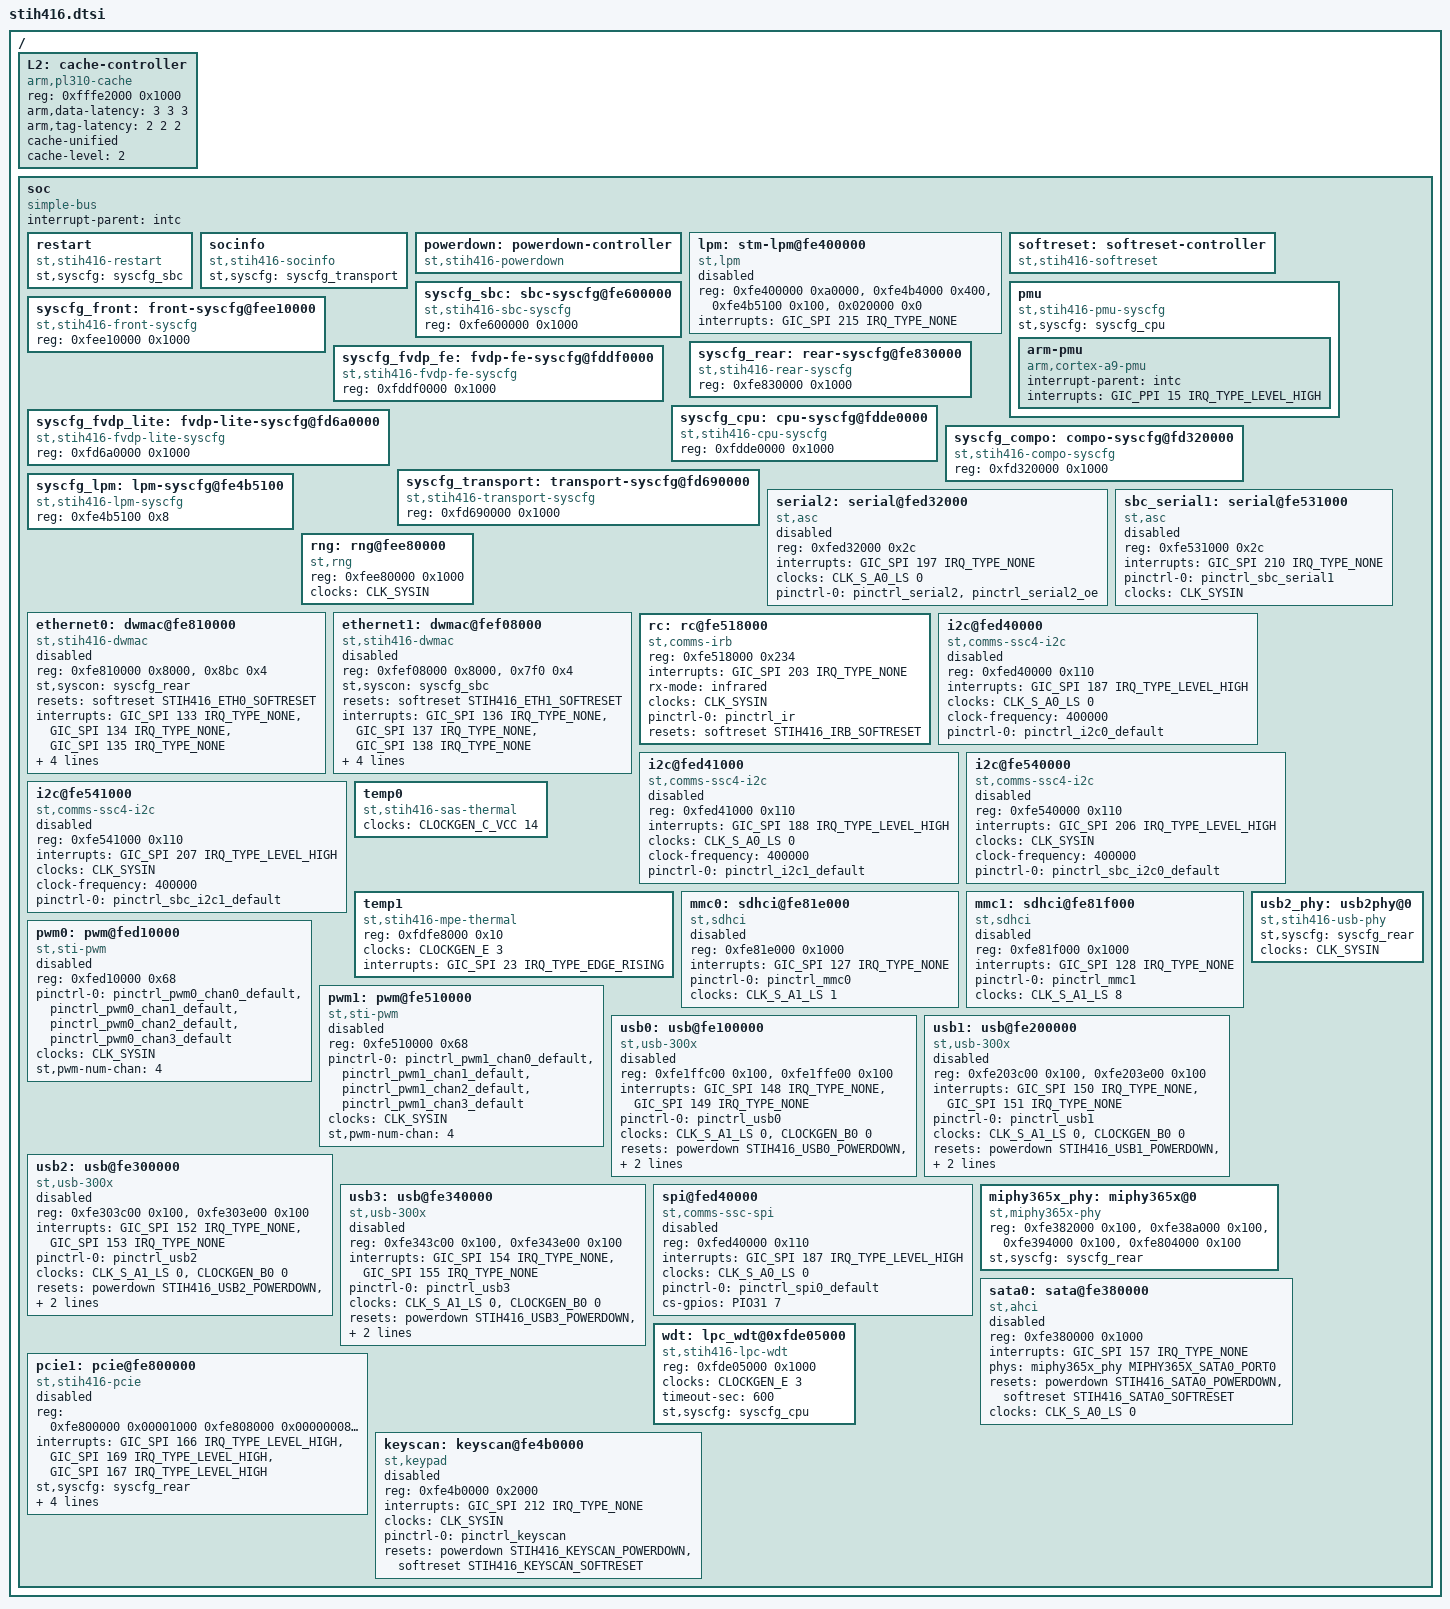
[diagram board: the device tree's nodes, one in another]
/*
 * Copyright (C) 2012 STMicroelectronics Limited.
 * Author: Srinivas Kandagatla <srinivas.kandagatla@st.com>
 *
 * This program is free software; you can redistribute it and/or modify
 * it under the terms of the GNU General Public License version 2 as
 * publishhed by the Free Software Foundation.
 */
#include <dt-bindings/interrupt-controller/arm-gic.h>
#include <dt-bindings/reset-controller/stih416-resets.h>
#include <dt-bindings/phy/phy-miphy365x.h>
#include "stih41x.dtsi"
#include "stih416-clock.dtsi"
#include "stih416-pinctrl.dtsi"
/ {
	L2: cache-controller {
		compatible = "arm,pl310-cache";
		reg = <0xfffe2000 0x1000>;
		arm,data-latency = <3 3 3>;
		arm,tag-latency = <2 2 2>;
		cache-unified;
		cache-level = <2>;
	};

	soc {
		#address-cells = <1>;
		#size-cells = <1>;
		interrupt-parent = <&intc>;
		ranges;
		compatible = "simple-bus";

		restart {
			compatible = "st,stih416-restart";
			st,syscfg = <&syscfg_sbc>;
		};

		socinfo {
			compatible = "st,stih416-socinfo";
			st,syscfg = <&syscfg_transport>;
		};

		powerdown: powerdown-controller {
			#reset-cells = <1>;
			compatible = "st,stih416-powerdown";
		};

		lpm:stm-lpm@fe400000 {
			compatible = "st,lpm";
			reg = <0xfe400000 0xa0000>,
			      <0xfe4b4000 0x400>,
			      <0xfe4b5100 0x100>,
			      <0x020000 0x0>;
			reg-names = "base", "mailbox", "confreg", "pmem";
			interrupts = <GIC_SPI 215 IRQ_TYPE_NONE>;
			status = "disabled";
		};

		softreset: softreset-controller {
			#reset-cells = <1>;
			compatible = "st,stih416-softreset";
		};

		pmu {
			compatible = "st,stih416-pmu-syscfg";
			st,syscfg = <&syscfg_cpu>;

			arm-pmu {
				interrupt-parent = <&intc>;
				compatible = "arm,cortex-a9-pmu";
				interrupts = <GIC_PPI 15 IRQ_TYPE_LEVEL_HIGH>;
			};
		};

		syscfg_sbc:sbc-syscfg@fe600000{
			compatible = "st,stih416-sbc-syscfg", "syscon";
			reg = <0xfe600000 0x1000>;
		};

		syscfg_front:front-syscfg@fee10000{
			compatible = "st,stih416-front-syscfg", "syscon";
			reg = <0xfee10000 0x1000>;
		};

		syscfg_rear:rear-syscfg@fe830000{
			compatible = "st,stih416-rear-syscfg", "syscon";
			reg = <0xfe830000 0x1000>;
		};

		/* MPE */
		syscfg_fvdp_fe:fvdp-fe-syscfg@fddf0000{
			compatible = "st,stih416-fvdp-fe-syscfg", "syscon";
			reg = <0xfddf0000 0x1000>;
		};

		syscfg_fvdp_lite:fvdp-lite-syscfg@fd6a0000{
			compatible = "st,stih416-fvdp-lite-syscfg", "syscon";
			reg = <0xfd6a0000 0x1000>;
		};

		syscfg_cpu:cpu-syscfg@fdde0000{
			compatible = "st,stih416-cpu-syscfg", "syscon";
			reg = <0xfdde0000 0x1000>;
		};

		syscfg_compo:compo-syscfg@fd320000{
			compatible = "st,stih416-compo-syscfg", "syscon";
			reg = <0xfd320000 0x1000>;
		};

		syscfg_transport:transport-syscfg@fd690000{
			compatible = "st,stih416-transport-syscfg", "syscon";
			reg = <0xfd690000 0x1000>;
		};

		syscfg_lpm:lpm-syscfg@fe4b5100{
			compatible = "st,stih416-lpm-syscfg", "syscon";
			reg = <0xfe4b5100 0x8>;
		};

		serial2: serial@fed32000{
			compatible = "st,asc";
			status = "disabled";
			reg = <0xfed32000 0x2c>;
			interrupts = <GIC_SPI 197 IRQ_TYPE_NONE>;
			clocks = <&CLK_S_A0_LS 0>;
			pinctrl-names = "default";
			pinctrl-0 = <&pinctrl_serial2 &pinctrl_serial2_oe>;
		};

		/* SBC_UART1 */
		sbc_serial1: serial@fe531000 {
			compatible = "st,asc";
			status = "disabled";
			reg = <0xfe531000 0x2c>;
			interrupts = <GIC_SPI 210 IRQ_TYPE_NONE>;
			pinctrl-names = "default";
			pinctrl-0 = <&pinctrl_sbc_serial1>;
			clocks = <&CLK_SYSIN>;
		};

		/* RNG */
		rng: rng@fee80000 {
			compatible = "st,rng";
			reg = <0xfee80000 0x1000>;
			clocks = <&CLK_SYSIN>;
		};

		ethernet0: dwmac@fe810000 {
			device_type = "network";
			status = "disabled";
			compatible = "st,stih416-dwmac", "snps,dwmac", "snps,dwmac-3.710";
			reg = <0xfe810000 0x8000>, <0x8bc 0x4>;
			reg-names = "stmmaceth", "sti-ethconf";
			st,syscon = <&syscfg_rear>;
			resets = <&softreset STIH416_ETH0_SOFTRESET>;
			reset-names = "stmmaceth";
			interrupts = <GIC_SPI 133 IRQ_TYPE_NONE>,
				     <GIC_SPI 134 IRQ_TYPE_NONE>,
				     <GIC_SPI 135 IRQ_TYPE_NONE>;

			interrupt-names = "macirq", "eth_wake_irq", "eth_lpi";

			snps,pbl = <32>;
			snps,mixed-burst;

			pinctrl-names = "default";
			pinctrl-0 = <&pinctrl_mii0>;
			clock-names = "stmmaceth", "sti-ethclk";
			clocks = <&CLK_S_A1_LS 0>, <&CLK_S_A1_LS 3>;
		};

		ethernet1: dwmac@fef08000 {
			device_type = "network";
			status = "disabled";
			compatible = "st,stih416-dwmac", "snps,dwmac", "snps,dwmac-3.710";
			reg = <0xfef08000 0x8000>, <0x7f0 0x4>;
			reg-names = "stmmaceth", "sti-ethconf";
			st,syscon = <&syscfg_sbc>;
			resets = <&softreset STIH416_ETH1_SOFTRESET>;
			reset-names = "stmmaceth";

			interrupts = <GIC_SPI 136 IRQ_TYPE_NONE>,
					     <GIC_SPI 137 IRQ_TYPE_NONE>,
					     <GIC_SPI 138 IRQ_TYPE_NONE>;

			interrupt-names = "macirq", "eth_wake_irq", "eth_lpi";

			snps,pbl = <32>;
			snps,mixed-burst;

			pinctrl-names = "default";
			pinctrl-0 = <&pinctrl_mii1>;
			clock-names = "stmmaceth", "sti-ethclk";
			clocks = <&CLK_S_A0_LS 0>, <&CLK_S_A0_LS 4>;
		};

		rc: rc@fe518000 {
			compatible = "st,comms-irb";
			reg = <0xfe518000 0x234>;
			interrupts = <GIC_SPI 203 IRQ_TYPE_NONE>;
			rx-mode = "infrared";
			clocks = <&CLK_SYSIN>;
			pinctrl-names = "default";
			pinctrl-0 = <&pinctrl_ir>;
			resets = <&softreset STIH416_IRB_SOFTRESET>;
		};

		i2c@fed40000 {
			compatible = "st,comms-ssc4-i2c";
			reg	= <0xfed40000 0x110>;
			interrupts = <GIC_SPI 187 IRQ_TYPE_LEVEL_HIGH>;
			#address-cells = <1>;
			#size-cells = <0>;
			clocks = <&CLK_S_A0_LS 0>;
			clock-names	= "ssc";
			clock-frequency = <400000>;
			pinctrl-names = "default";
			pinctrl-0 = <&pinctrl_i2c0_default>;

			status = "disabled";
		};

		i2c@fed41000 {
			compatible = "st,comms-ssc4-i2c";
			reg = <0xfed41000 0x110>;
			interrupts = <GIC_SPI 188 IRQ_TYPE_LEVEL_HIGH>;
			#address-cells = <1>;
			#size-cells = <0>;
			clocks = <&CLK_S_A0_LS 0>;
			clock-names	= "ssc";
			clock-frequency = <400000>;
			pinctrl-names = "default";
			pinctrl-0 = <&pinctrl_i2c1_default>;

			status = "disabled";
		};

		i2c@fe540000 {
			compatible = "st,comms-ssc4-i2c";
			reg = <0xfe540000 0x110>;
			interrupts = <GIC_SPI 206 IRQ_TYPE_LEVEL_HIGH>;
			#address-cells = <1>;
			#size-cells = <0>;
			clocks = <&CLK_SYSIN>;
			clock-names = "ssc";
			clock-frequency = <400000>;
			pinctrl-names = "default";
			pinctrl-0 = <&pinctrl_sbc_i2c0_default>;

			status = "disabled";
		};

		i2c@fe541000 {
			compatible = "st,comms-ssc4-i2c";
			reg = <0xfe541000 0x110>;
			interrupts = <GIC_SPI 207 IRQ_TYPE_LEVEL_HIGH>;
			#address-cells = <1>;
			#size-cells = <0>;
			clocks = <&CLK_SYSIN>;
			clock-names = "ssc";
			clock-frequency = <400000>;
			pinctrl-names = "default";
			pinctrl-0 = <&pinctrl_sbc_i2c1_default>;

			status = "disabled";
		};

		temp0{
			compatible = "st,stih416-sas-thermal";
			clock-names = "thermal";
			clocks = <&CLOCKGEN_C_VCC 14>;
		};

		temp1{
			compatible = "st,stih416-mpe-thermal";
			reg = <0xfdfe8000 0x10>;
			clock-names = "thermal";
			clocks = <&CLOCKGEN_E 3>;
			interrupts = <GIC_SPI 23 IRQ_TYPE_EDGE_RISING>;
		};

		mmc0: sdhci@fe81e000 {
			compatible = "st,sdhci";
			status = "disabled";
			reg = <0xfe81e000 0x1000>;
			interrupts = <GIC_SPI 127 IRQ_TYPE_NONE>;
			interrupt-names = "mmcirq";
			pinctrl-names = "default";
			pinctrl-0 = <&pinctrl_mmc0>;
			clock-names	= "mmc";
			clocks = <&CLK_S_A1_LS 1>;
		};

		mmc1: sdhci@fe81f000 {
			compatible = "st,sdhci";
			status = "disabled";
			reg = <0xfe81f000 0x1000>;
			interrupts = <GIC_SPI 128 IRQ_TYPE_NONE>;
			interrupt-names = "mmcirq";
			pinctrl-names = "default";
			pinctrl-0 = <&pinctrl_mmc1>;
			clock-names	= "mmc";
			clocks = <&CLK_S_A1_LS 8>;
		};

		/* SAS PWM MODULE */
		pwm0: pwm@fed10000 {
			compatible = "st,sti-pwm";
			status = "disabled";
			#pwm-cells = <2>;
			reg = <0xfed10000 0x68>;
			pinctrl-names = "default";
			pinctrl-0 = <&pinctrl_pwm0_chan0_default
				     &pinctrl_pwm0_chan1_default
				     &pinctrl_pwm0_chan2_default
				     &pinctrl_pwm0_chan3_default>;
			clock-names = "pwm";
			clocks = <&CLK_SYSIN>;
			st,pwm-num-chan = <4>;
		};

		/* SBC PWM MODULE */
		pwm1: pwm@fe510000 {
			compatible = "st,sti-pwm";
			status = "disabled";
			#pwm-cells = <2>;
			reg = <0xfe510000 0x68>;
			pinctrl-names = "default";
			pinctrl-0 = <&pinctrl_pwm1_chan0_default
				     &pinctrl_pwm1_chan1_default
				     &pinctrl_pwm1_chan2_default
				     &pinctrl_pwm1_chan3_default>;
			clock-names = "pwm";
			clocks = <&CLK_SYSIN>;
			st,pwm-num-chan = <4>;
		};

		usb2_phy: usb2phy@0 {
			compatible = "st,stih416-usb-phy";
			#phy-cells = <0>;

			st,syscfg = <&syscfg_rear>;

			clocks = <&CLK_SYSIN>;
			clock-names = "osc_phy";
		};

		usb0: usb@fe100000 {
			compatible = "st,usb-300x";
			status = "disabled";
			reg = <0xfe1ffc00 0x100>,
				  <0xfe1ffe00 0x100>;
			reg-names = "ohci", "ehci";

			interrupts = <GIC_SPI 148 IRQ_TYPE_NONE>,
				     <GIC_SPI 149 IRQ_TYPE_NONE>;
			interrupt-names = "ehci","ohci";
			pinctrl-names = "default";
			pinctrl-0 = <&pinctrl_usb0>;
			clocks = <&CLK_S_A1_LS 0>,
				 <&CLOCKGEN_B0 0>;
			clock-names = "ic", "ohci";

			resets = <&powerdown STIH416_USB0_POWERDOWN>,
				 <&softreset STIH416_USB0_SOFTRESET>;
			reset-names = "power", "softreset";

			phys = <&usb2_phy>;
			phy-names = "usb2-phy";
		};

		usb1: usb@fe200000 {
			compatible = "st,usb-300x";
			status = "disabled";
			reg = <0xfe203c00 0x100>,
			      <0xfe203e00 0x100>;
			reg-names = "ohci", "ehci";

			interrupts = <GIC_SPI 150 IRQ_TYPE_NONE>,
				     <GIC_SPI 151 IRQ_TYPE_NONE>;
			interrupt-names = "ehci","ohci";
			pinctrl-names = "default";
			pinctrl-0 = <&pinctrl_usb1>;
			clocks = <&CLK_S_A1_LS 0>,
				 <&CLOCKGEN_B0 0>;
			clock-names = "ic", "ohci";

			resets = <&powerdown STIH416_USB1_POWERDOWN>,
				 <&softreset STIH416_USB1_SOFTRESET>;
			reset-names = "power", "softreset";

			phys = <&usb2_phy>;
			phy-names = "usb2-phy";
		};

		usb2: usb@fe300000 {
			compatible = "st,usb-300x";
			status = "disabled";
			reg = <0xfe303c00 0x100>,
			      <0xfe303e00 0x100>;
			reg-names = "ohci", "ehci";

			interrupts = <GIC_SPI 152 IRQ_TYPE_NONE>,
				     <GIC_SPI 153 IRQ_TYPE_NONE>;
			interrupt-names = "ehci","ohci";
			pinctrl-names = "default";
			pinctrl-0 = <&pinctrl_usb2>;
			clocks = <&CLK_S_A1_LS 0>,
				 <&CLOCKGEN_B0 0>;
			clock-names = "ic", "ohci";

			resets = <&powerdown STIH416_USB2_POWERDOWN>,
				 <&softreset STIH416_USB2_SOFTRESET>;
			reset-names = "power", "softreset";

			phys = <&usb2_phy>;
			phy-names = "usb2-phy";
		};

		usb3: usb@fe340000 {
			compatible = "st,usb-300x";
			status = "disabled";
			reg = <0xfe343c00 0x100>, <0xfe343e00 0x100>;
			reg-names = "ohci", "ehci";

			interrupts = <GIC_SPI 154 IRQ_TYPE_NONE>,
				     <GIC_SPI 155 IRQ_TYPE_NONE>;
			interrupt-names = "ehci","ohci";
			pinctrl-names = "default";
			pinctrl-0 = <&pinctrl_usb3>;
			clocks = <&CLK_S_A1_LS 0>,
				 <&CLOCKGEN_B0 0>;
			clock-names = "ic", "ohci";

			resets = <&powerdown STIH416_USB3_POWERDOWN>,
				 <&softreset STIH416_USB3_SOFTRESET>;
			reset-names = "power", "softreset";

			phys = <&usb2_phy>;
			phy-names = "usb2-phy";
		};

		/* SSC0 */
		spi@fed40000 {
			compatible = "st,comms-ssc-spi";
			reg = <0xfed40000 0x110>;
			interrupts = <GIC_SPI 187 IRQ_TYPE_LEVEL_HIGH>;
			clocks = <&CLK_S_A0_LS 0>;
			clock-names = "ssc";
			pinctrl-names = "default";
			pinctrl-0 = <&pinctrl_spi0_default>;
			cs-gpios = <&PIO31 7 0>;

			status = "disabled";
		};

		miphy365x_phy: miphy365x@0 {
			compatible = "st,miphy365x-phy";
			#phy-cells = <1>;
			reg = <0xfe382000 0x100>,
			      <0xfe38a000 0x100>,
			      <0xfe394000 0x100>,
			      <0xfe804000 0x100>;
			reg-names = "sata0", "sata1", "pcie0", "pcie1";
			st,syscfg= <&syscfg_rear>;
		};

		sata0: sata@fe380000 {
			compatible = "st,ahci";
			reg = <0xfe380000 0x1000>;
			interrupts = <GIC_SPI 157 IRQ_TYPE_NONE>;
			interrupt-names = "hostc";
			status = "disabled";
			phys = <&miphy365x_phy MIPHY365X_SATA0_PORT0>;
			phy-names = "ahci_phy";
			resets = <&powerdown STIH416_SATA0_POWERDOWN>,
				 <&softreset STIH416_SATA0_SOFTRESET>;
			reset-names = "pwr-dwn", "sw-rst";
			clock-names = "ahci_clk";
			clocks = <&CLK_S_A0_LS 0>;
		};

		pcie1: pcie@fe800000 {
			compatible = "st,stih416-pcie";
			device_type = "pci";
			reg = <0xfe800000 0x00001000   /* cntrl registers */
			       0xfe808000 0x00000008   /* ahb registers */
			       0x2fff0000 0x00010000   /* configuration space */
			       0x40000000 0x80000000   /* lmi mem window */
			      0x82C 0x04>;            /* syscfg 2523 */
			reg-names = "pcie cntrl", "pcie ahb", "pcie cs", "mem-window",
				    "syscfg0";

			interrupts = <GIC_SPI 166 IRQ_TYPE_LEVEL_HIGH>,
				     <GIC_SPI 169 IRQ_TYPE_LEVEL_HIGH>,
				     <GIC_SPI 167 IRQ_TYPE_LEVEL_HIGH>;
			interrupt-names = "pcie inta", "pcie syserr", "msi";

			#address-cells = <3>;
			#size-cells = <2>;
			ranges = <0x82000000 0 0x20000000 0x20000000 0 0x05550000   /* non-prefetchable memory */
				  0xc2000000 0 0x25550000 0x25550000 0 0x0AAA0000>; /* prefetchable memory */
			st,syscfg = <&syscfg_rear>;
			st,ahb-fixup = <0x26C208>;

			resets = <&powerdown STIH416_PCIE1_POWERDOWN>,
				 <&softreset STIH416_PCIE1_SOFTRESET>;
			reset-names = "power", "softreset";

			phys = <&miphy365x_phy MIPHY365X_PCIE1_PORT1>;
			phy-names = "pcie_phy";

			status = "disabled";
		};

		wdt: lpc_wdt@0xfde05000 {
			compatible = "st,stih416-lpc-wdt";
			reg = <0xfde05000 0x1000>;
			clock-names = "lpc_wdt";
			clocks = <&CLOCKGEN_E 3>;
			timeout-sec = <600>;
			st,syscfg = <&syscfg_cpu>;
		};

		keyscan: keyscan@fe4b0000 {
			compatible = "st,keypad";
			status = "disabled";
			reg = <0xfe4b0000 0x2000>;
			interrupts = <GIC_SPI 212 IRQ_TYPE_NONE>;
			clocks	= <&CLK_SYSIN>;
			pinctrl-names = "default";
			pinctrl-0 = <&pinctrl_keyscan>;
			resets	= <&powerdown STIH416_KEYSCAN_POWERDOWN>,
				  <&softreset STIH416_KEYSCAN_SOFTRESET>;
		};
	};
};
